# XMC4100 register map
Vendor: Infineon; File version: 1.5.2 (Reference Manual v1.5)
CPU: CM4 r2p0, little endian, MPU, FPU, 6 interrupt priority bits
Registers are 32-bit, read-write, reset 0x0 unless marked. A register's access mark holds for its fields unless they carry their own. Offsets are from the block's base; [hi:lo] are bit positions; {n}, {i} and the like mark numbered series; 'fields as' and 'values as' point back to an identical list.

## HRPWM0 — High Resolution PWM Unit
Base 0x40020900
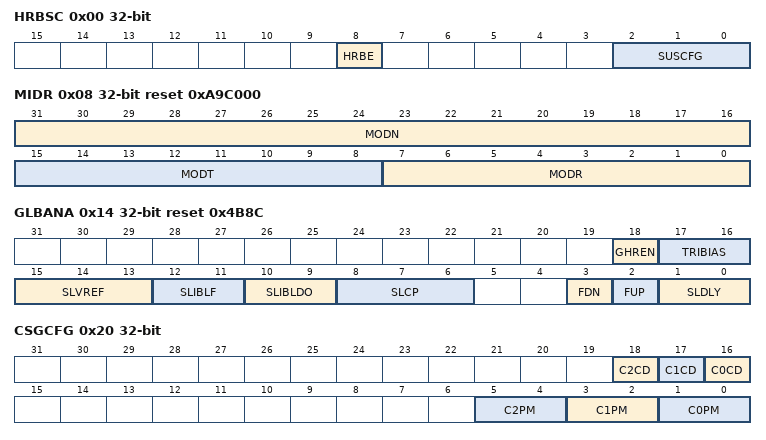
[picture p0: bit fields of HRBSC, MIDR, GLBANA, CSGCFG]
0x00 HRBSC — Bias and suspend configuration
  [8] HRBE — HRPWM bias enable
  [2:0] SUSCFG — Suspend configuration
    0=Suspend is ignored; 1=CSGy and HRCy units are halted; 2=Comparator outputs, HRPWMx.CyO are clamped to passive level and the CSGy units are halted. High resolution channel outputs, HRPWMx.HROUTy0 and HRPWMx.HROUTy1, are clamped to passive state and the HRCy units are halted.; 3=CSGy units are halted. High resolution channel outputs, HRPWMx.HROUTy0 and HRPWMx.HROUTy1, are clamped to passive state and the HRCy units are halted.
0x08 MIDR ro reset 0xA9C000 (reset mask 0xFFFFFF00) — Module identification register
  [31:16] MODN — Module Number
  [15:8] MODT — Module Type
  [7:0] MODR — Module Revision
0x14 GLBANA reset 0x4B8C — Global Analog Configuration
  [18] GHREN — Force chargepump down
    0=Global high resolution generation is enabled; 1=Global high resolution generation is disabled
  [17:16] TRIBIAS — Bias trimming
  [15:13] SLVREF — Reference voltage for chargepump and loop filter
  [12:11] SLIBLF — HRCs loop filter bias current
  [10:9] SLIBLDO — HRCs LDO bias current
  [8:6] SLCP — HRCs chargepump current selection
  [3] FDN — Force chargepump down
  [2] FUP — Force chargepump up
  [1:0] SLDLY — Delay of lock detection
0x20 CSGCFG — Global CSG configuration
  [18] C2CD — CSG2 Clock disable
  [17] C1CD — CSG1 Clock disable
  [16] C0CD — CSG0 Clock disable
  [5:4] C2PM — CSG2 Power Mode
    0=CSG2 unit is powered OFF; 1=CSG2 unit is set in Low Speed Mode; 3=CSG2 unit is set in High Speed Mode
  [3:2] C1PM — CSG1 Power Mode
    0=CSG1 unit is powered OFF; 1=CSG1 unit is set in Low Speed Mode; 3=CSG1 unit is set in High Speed Mode
  [1:0] C0PM — CSG0 Power Mode
    0=CSG0 unit is powered OFF; 1=CSG0 unit is set in Low Speed Mode; 3=CSG0 unit is set in High Speed Mode
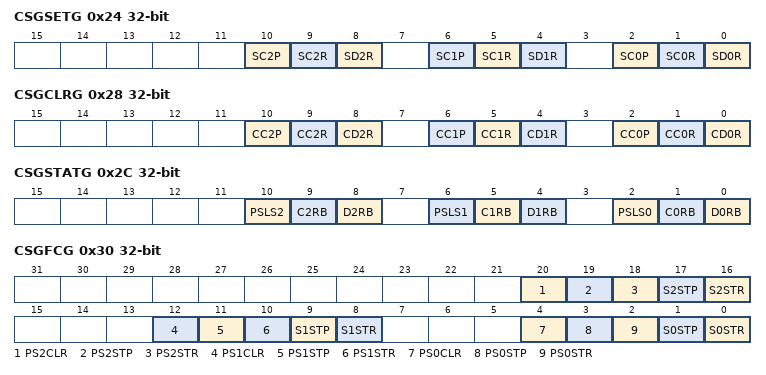
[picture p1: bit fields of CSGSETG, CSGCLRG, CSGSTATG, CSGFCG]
0x24 CSGSETG wo — Global CSG run bit set
  [10] SC2P — CMP2 passive level set
  [9] SC2R — CMP2 run bit set
  [8] SD2R — DAC2 run bit set
  [6] SC1P — CMP1 passive level set
  [5] SC1R — CMP1 run bit set
  [4] SD1R — DAC1 run bit set
  [2] SC0P — CMP0 passive level set
  [1] SC0R — CMP0 run bit set
  [0] SD0R — DAC0 run bit set
0x28 CSGCLRG wo — Global CSG run bit clear
  [10] CC2P — CMP2 passive level clear
  [9] CC2R — CMP2 run bit clear
  [8] CD2R — DAC2 run bit clear
  [6] CC1P — CMP1 passive level clear
  [5] CC1R — CMP1 run bit clear
  [4] CD1R — DAC1 run bit clear
  [2] CC0P — CMP0 passive level clear
  [1] CC0R — CMP0 run bit clear
  [0] CD0R — DAC0 run bit clear
0x2C CSGSTATG ro — Global CSG run bit status
  [10] PSLS2 — CMP2 output passive status
    0=CMP2 output is not clamped; 1=CMP2 output is clamped
  [9] C2RB — CMP2 run bit status
    0=CMP2 functionality is disabled; 1=CMP2 functionality is enabled
  [8] D2RB — DAC2 run bit status
    0=DAC2 is not running (control logic is disabled); 1=DAC1 is running
  [6] PSLS1 — CMP1 output passive status
    0=CMP1 output is not clamped; 1=CMP1 output is clamped
  [5] C1RB — CMP1 run bit status
    0=CMP1 functionality is disabled; 1=CMP1 functionality is enabled
  [4] D1RB — DAC1 run bit status
    0=DAC1 is not running (control logic is disabled); 1=DAC1 is running
  [2] PSLS0 — CMP0 output passive status
    0=CMP0 output is not clamped; 1=CMP0 output is clamped
  [1] C0RB — CMP0 run bit status
    0=CMP0 functionality is disabled; 1=CMP0 functionality is enabled
  [0] D0RB — DAC0 run bit status
    0=DAC0 is not running (control logic is disabled); 1=DAC0 is running
0x30 CSGFCG wo — Global CSG slope/prescaler control
  [20] PS2CLR — Prescaler 2 clear
  [19] PS2STP — Prescaler 2 stop
  [18] PS2STR — Prescaler 2 start
  [17] S2STP — Slope 2 stop
  [16] S2STR — Slope 2 start
  [12] PS1CLR — Prescaler 1 clear
  [11] PS1STP — Prescaler 1 stop
  [10] PS1STR — Prescaler 1 start
  [9] S1STP — Slope 1 stop
  [8] S1STR — Slope 1 start
  [4] PS0CLR — Prescaler 0 clear
  [3] PS0STP — Prescaler 0 stop
  [2] PS0STR — Prescaler 0 start
  [1] S0STP — Slope 0 stop
  [0] S0STR — Slope 0 start
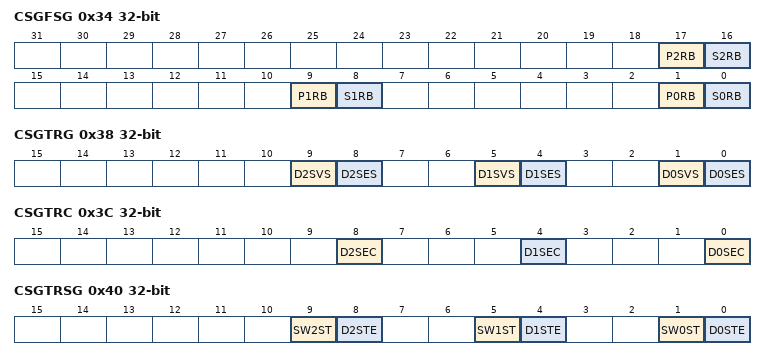
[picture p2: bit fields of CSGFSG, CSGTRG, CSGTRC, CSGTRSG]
0x34 CSGFSG ro — Global CSG slope/prescaler status
  [17] P2RB — CSG2 prescaler status
    0=Prescaler is stopped. The clock used for the slope generation is halted and therefore the slope is frozen.; 1=Prescaler is running
  [16] S2RB — DAC2 slope generation status
    0=Slope generation is stopped; 1=Slope generation is running
  [9] P1RB — CSG1 prescaler status
    values as P2RB
  [8] S1RB — DAC1 slope generation status
    0=Slope generation is stopped; 1=Slope generation is running
  [1] P0RB — CSG0 prescaler status
    values as P2RB
  [0] S0RB — DAC0 slope generation status
    0=Slope generation is stopped; 1=Slope generation is running
0x38 CSGTRG wo — Global CSG shadow/switch trigger
  [9] D2SVS — CMP2 inverting input switch request
  [8] D2SES — DAC2 shadow transfer enable set
  [5] D1SVS — CMP1 inverting input switch request
  [4] D1SES — DAC1 shadow transfer enable set
  [1] D0SVS — CMP0 inverting input switch request
  [0] D0SES — DAC0 shadow transfer enable set
0x3C CSGTRC wo — Global CSG shadow trigger clear
  [8] D2SEC — DAC2 shadow transfer enable clear
  [4] D1SEC — DAC1 shadow transfer enable clear
  [0] D0SEC — DAC0 shadow transfer enable clear
0x40 CSGTRSG ro — Global CSG shadow/switch status
  [9] SW2ST — CMP2 inverting input connection status
    0=Inverting input connected to HRPWMx.C2I[A]; 1=Inverting input connected to HRPWMx.C2I[B]
  [8] D2STE — DAC2 shadow transfer enable
    0=Shadow transfer has been performed; 1=Shadow transfer has been requested but is still pending completion
  [5] SW1ST — CMP1 inverting input connection status
    0=Inverting input connected to HRPWMx.C1I[A]; 1=Inverting input connected to HRPWMx.C1I[B]
  [4] D1STE — DAC1 shadow transfer enable
    values as D2STE
  [1] SW0ST — CMP0 inverting input connection status
    0=Inverting input connected to HRPWMx.C0I[A]; 1=Inverting input connected to HRPWMx.C0I[B]
  [0] D0STE — DAC0 shadow transfer enable
    values as D2STE
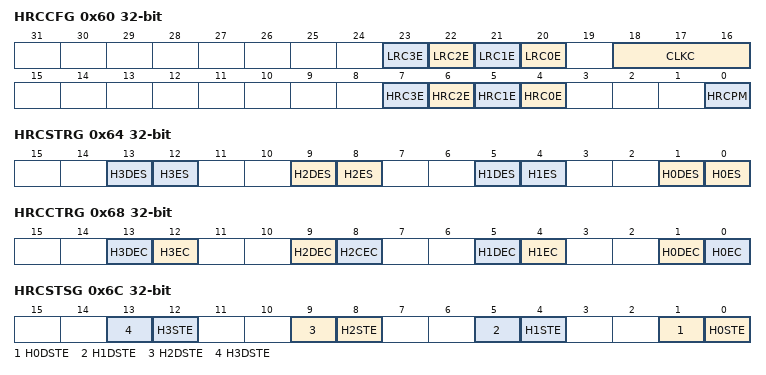
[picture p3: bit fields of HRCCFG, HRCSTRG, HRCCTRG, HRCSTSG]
0x60 HRCCFG — Global HRC configuration
  [n+20] LRC{n}E (n=0..3) — HRC{n} low resolution channel enable
    0=HRC{n} Low Resolution Path is disabled. In this mode, is not possible to use the Low Resolution Path inside of HRC{n} to generate an output PWM signal.; 1=HRC{n} Low Resolution Path is enabled. In this mode it is possible to generate a an output PWM signal via the Low Resolution Path.
  [18:16] CLKC — Clock information control
    0=No clock frequency is selected; 1=Module clock frequency is 180 MHz; 2=Module clock frequency is 120 MHz; 3=Module clock frequency is 80 MHz
  [7] HRC3E — HRC3 high resolution channel enable
    0=HRC3 High Resolution Path is disabled. In this mode, is not possible to use the High Resolution Path inside of HRC3 to generate an output PWM signal.; 1=HRC3 High Resolution Path is enabled. In this mode it is possible to generate a high resolution PWM signal if HRCPM = 1#.
  [6] HRC2E — HRC2 high resolution channel enable
    0=HRC2 High Resolution Path is disabled. In this mode, is not possible to use the High Resolution Path inside of HRC2 to generate an output PWM signal.; 1=HRC2 High Resolution Path is enabled. In this mode it is possible to generate a high resolution PWM signal if HRCPM = 1#.
  [5] HRC1E — HRC1 high resolution channel enable
    0=HRC1 High Resolution Path is disabled. In this mode, is not possible to use the High Resolution Path inside of HRC1 to generate an output PWM signal.; 1=HRC1 High Resolution Path is enabled. In this mode it is possible to generate a high resolution PWM signal if HRCPM = 1#.
  [4] HRC0E — HRC0 high resolution enable
    0=HRC0 High Resolution Path is disabled. In this mode, is not possible to use the High Resolution Path inside of HRC0 to generate an output PWM signal.; 1=HRC0 High Resolution Path is enabled. In this mode it is possible to generate a high resolution PWM signal if HRCPM = 1#.
  [0] HRCPM — High resolution channels power mode
    0=High resolution generation logic is OFF. It is not possible to generate high resolution signals throughout any of the high resolution channels, HRCy.; 1=High resolution generation logic is ON. In this mode it is possible to generate a high resolution signal placement with the HRCy subunits.
0x64 HRCSTRG wo — Global HRC shadow trigger set
  [4n+1] H{n}DES (n=0..3) — HRC0 dead time value shadow transfer enable set
  [4n] H{n}ES (n=0..3) — HRC{n} high resolution values shadow transfer Enable Set
0x68 HRCCTRG wo — Global HRC shadow trigger clear
  [4n+1] H{n}DEC (n=0..3) — HRC{n} dead time value shadow transfer Enable Clear
  [12] H3EC — HRC3 high resolution values shadow transfer Enable Clear
  [8] H2CEC — HRC2 high resolution values shadow transfer Enable Clear
  [4] H1EC — HRC1 high resolution values shadow transfer Enable Clear
  [0] H0EC — HRC0 high resolution values shadow transfer Enable Clear
0x6C HRCSTSG ro — Global HRC shadow transfer status
  [4n+1] H{n}DSTE (n=0..3) — HRC{n} dead time value shadow transfer status
    0=No shadow transfer pending for HRCyDCRThis register holds the dead time value that is going to be inserted whenever a rising transition on the output latch is sensed. and HRCyDCFThis register holds the dead time value that is going to be inserted whenever a falling transition on the output latch is sensed. values; 1=Shadow transfer pending for HRCyDCRThis register holds the dead time value that is going to be inserted whenever a rising transition on the output latch is sensed. and HRCyDCFThis register holds the dead time value that is going to be inserted whenever a falling transition on the output latch is sensed. values
  [4n] H{n}STE (n=0..3) — HRC{n} high resolution values shadow transfer status
    0=No shadow transfer pending for HRCyCR1This register holds the value for the rising edge high resolution signal placement. the update of this value should be done via the associated shadow register, . and HRCyCR2This register holds the value for the falling edge high resolution signal placement. the update of this value should be done via the associated shadow register, . values; 1=Shadow transfer pending for HRCyCR1This register holds the value for the rising edge high resolution signal placement. the update of this value should be done via the associated shadow register, . and HRCyCR2This register holds the value for the falling edge high resolution signal placement. the update of this value should be done via the associated shadow register, . values
0x70 HRGHRS ro — High Resolution Generation Status
  [0] HRGR — High Resolution Generation Ready
    0=High resolution logic is not working; 1=High resolution logic is working
